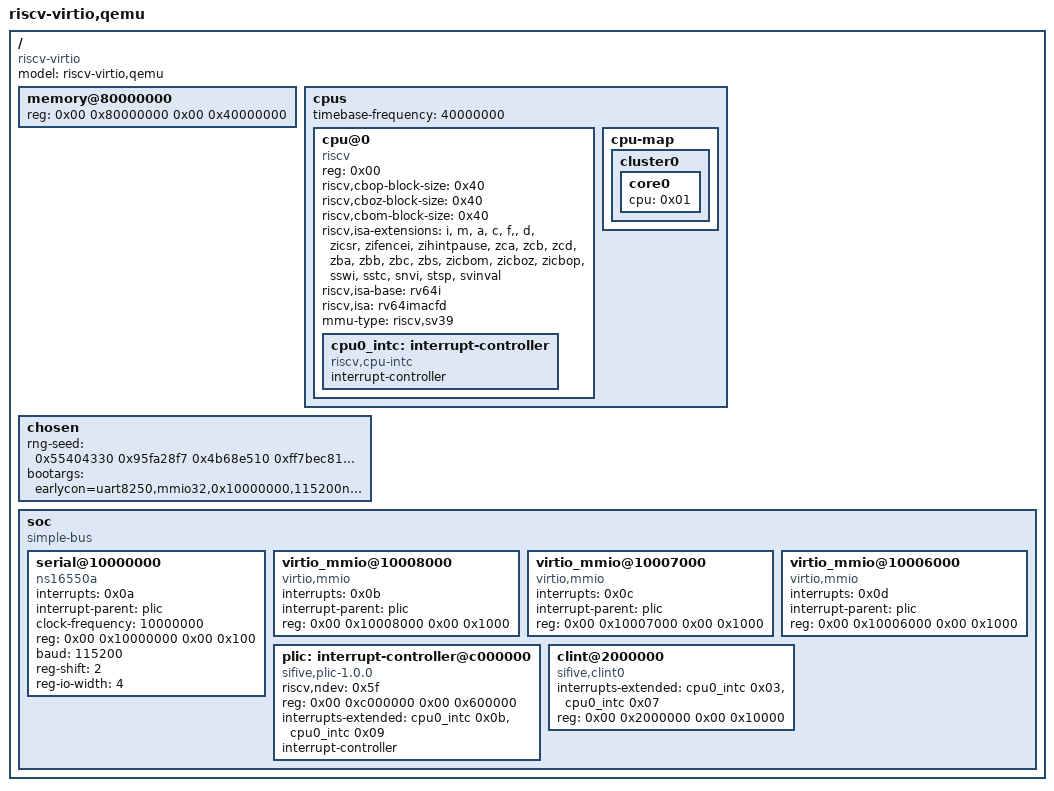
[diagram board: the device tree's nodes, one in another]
/dts-v1/;

/ {
	#address-cells = <0x02>;
	#size-cells = <0x02>;
	compatible = "riscv-virtio";
	model = "riscv-virtio,qemu";

	memory@80000000 {
		device_type = "memory";
		reg = <0x00 0x80000000 0x00 0x40000000>;
	};

	cpus {
		#address-cells = <0x01>;
		#size-cells = <0x00>;
		timebase-frequency = <40000000>;

		cpu@0 {
			phandle = <0x01>;
			device_type = "cpu";
			reg = <0x00>;
			status = "okay";
			compatible = "riscv";
			riscv,cbop-block-size = <0x40>;
			riscv,cboz-block-size = <0x40>;
			riscv,cbom-block-size = <0x40>;
			riscv,isa-extensions = "i","m","a","c","f,","d",
					       "zicsr","zifencei","zihintpause","zca","zcb","zcd",
					       "zba","zbb","zbc","zbs","zicbom","zicboz","zicbop",
					       "sswi","sstc","snvi","stsp","svinval";
			riscv,isa-base = "rv64i";
			riscv,isa = "rv64imacfd";
			mmu-type = "riscv,sv39";

			cpu0_intc: interrupt-controller {
				#interrupt-cells = <0x01>;
				interrupt-controller;
				compatible = "riscv,cpu-intc";
			};
		};

		cpu-map {
			cluster0 {
				core0 {
					cpu = <0x01>;
				};
			};
		};
	};


	chosen {
		rng-seed = <0x55404330 0x95fa28f7 0x4b68e510 0xff7bec81 0xffe0df4d 0x9d97558 0x42719e74 0xb6f0ec>;
		bootargs = "earlycon=uart8250,mmio32,0x10000000,115200n8 console=ttyS0,115200n8 root=/dev/vda1 rw print-fatal-signals=1";
	};

	soc {
		#address-cells = <0x02>;
		#size-cells = <0x02>;
		compatible = "simple-bus";
		ranges;

		serial@10000000 {
			interrupts = <0x0a>;
			interrupt-parent = <&plic>;
			clock-frequency = <10000000>;
			reg = <0x00 0x10000000 0x00 0x100>;
			baud = <115200>;
			reg-shift = <2>;
			reg-io-width = <4>;
			compatible = "ns16550a";
		};

		virtio_mmio@10008000 {
			interrupts = <0x0b>;
			interrupt-parent = <&plic>;
			reg = <0x00 0x10008000 0x00 0x1000>;
			compatible = "virtio,mmio";
		};

		virtio_mmio@10007000 {
			interrupts = <0x0c>;
			interrupt-parent = <&plic>;
			reg = <0x00 0x10007000 0x00 0x1000>;
			compatible = "virtio,mmio";
		};

		virtio_mmio@10006000 {
			interrupts = <0x0d>;
			interrupt-parent = <&plic>;
			reg = <0x00 0x10006000 0x00 0x1000>;
			compatible = "virtio,mmio";
		};

		plic: interrupt-controller@c000000 {
			riscv,ndev = <0x5f>;
			reg = <0x00 0xc000000 0x00 0x600000>;
			interrupts-extended = <&cpu0_intc 0x0b &cpu0_intc 0x09>;
			interrupt-controller;
			compatible = "sifive,plic-1.0.0","riscv,plic0";
			#address-cells = <0x00>;
			#interrupt-cells = <0x01>;
		};

		clint@2000000 {
			interrupts-extended = <&cpu0_intc 0x03 &cpu0_intc 0x07>;
			reg = <0x00 0x2000000 0x00 0x10000>;
			compatible = "sifive,clint0","riscv,clint0";
		};
	};
};
